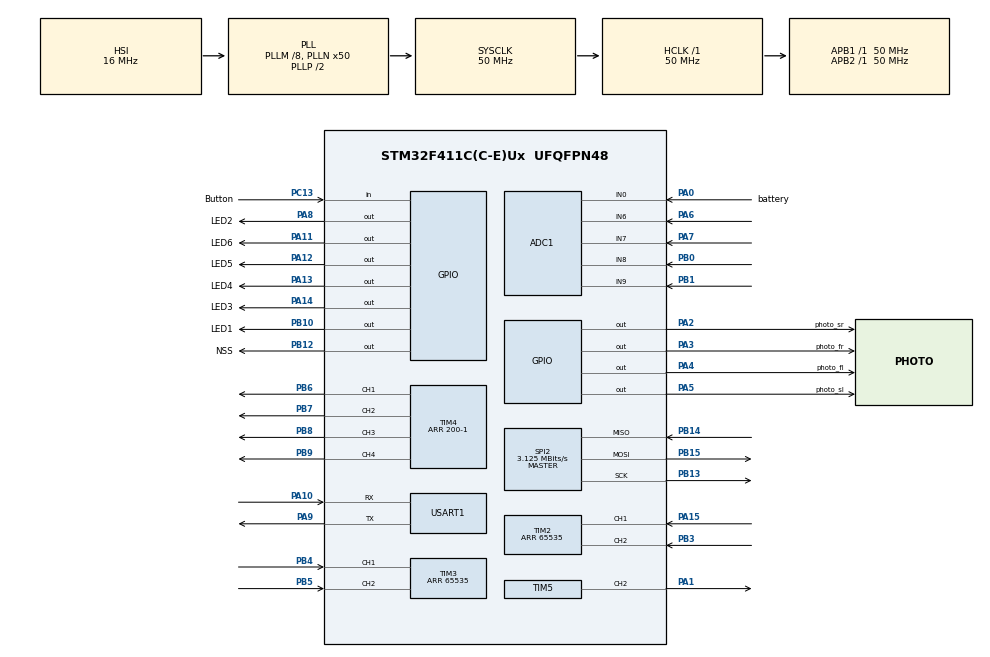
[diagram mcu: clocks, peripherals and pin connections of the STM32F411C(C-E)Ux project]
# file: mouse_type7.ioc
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ADC1.Channel-0\#ChannelRegularConversion=ADC_CHANNEL_7
ADC1.Channel-10\#ChannelRegularConversion=ADC_CHANNEL_0
ADC1.Channel-2\#ChannelRegularConversion=ADC_CHANNEL_7
ADC1.Channel-3\#ChannelRegularConversion=ADC_CHANNEL_8
ADC1.Channel-4\#ChannelRegularConversion=ADC_CHANNEL_8
ADC1.Channel-5\#ChannelRegularConversion=ADC_CHANNEL_6
ADC1.Channel-6\#ChannelRegularConversion=ADC_CHANNEL_6
ADC1.Channel-7\#ChannelRegularConversion=ADC_CHANNEL_9
ADC1.Channel-8\#ChannelRegularConversion=ADC_CHANNEL_9
ADC1.Channel-9\#ChannelRegularConversion=ADC_CHANNEL_0
ADC1.DMAContinuousRequests=ENABLE
ADC1.DiscontinuousConvMode=ENABLE
ADC1.EOCSelection=ADC_EOC_SEQ_CONV
ADC1.ExternalTrigConv=ADC_EXTERNALTRIGCONV_T1_CC3
ADC1.ExternalTrigConvEdge=ADC_EXTERNALTRIGCONVEDGE_FALLING
ADC1.NbrOfConversion=10
ADC1.NbrOfConversionFlag=1
ADC1.Rank-0\#ChannelRegularConversion=1
ADC1.Rank-10\#ChannelRegularConversion=10
ADC1.Rank-2\#ChannelRegularConversion=2
ADC1.Rank-3\#ChannelRegularConversion=3
ADC1.Rank-4\#ChannelRegularConversion=4
ADC1.Rank-5\#ChannelRegularConversion=5
ADC1.Rank-6\#ChannelRegularConversion=6
ADC1.Rank-7\#ChannelRegularConversion=7
ADC1.Rank-8\#ChannelRegularConversion=8
ADC1.Rank-9\#ChannelRegularConversion=9
ADC1.SamplingTime-0\#ChannelRegularConversion=ADC_SAMPLETIME_28CYCLES
ADC1.SamplingTime-10\#ChannelRegularConversion=ADC_SAMPLETIME_28CYCLES
ADC1.SamplingTime-2\#ChannelRegularConversion=ADC_SAMPLETIME_28CYCLES
ADC1.SamplingTime-3\#ChannelRegularConversion=ADC_SAMPLETIME_28CYCLES
ADC1.SamplingTime-4\#ChannelRegularConversion=ADC_SAMPLETIME_28CYCLES
ADC1.SamplingTime-5\#ChannelRegularConversion=ADC_SAMPLETIME_28CYCLES
ADC1.SamplingTime-6\#ChannelRegularConversion=ADC_SAMPLETIME_28CYCLES
ADC1.SamplingTime-7\#ChannelRegularConversion=ADC_SAMPLETIME_28CYCLES
ADC1.SamplingTime-8\#ChannelRegularConversion=ADC_SAMPLETIME_28CYCLES
ADC1.SamplingTime-9\#ChannelRegularConversion=ADC_SAMPLETIME_28CYCLES
ADC1.master=1
Dma.ADC1.0.Direction=DMA_PERIPH_TO_MEMORY
Dma.ADC1.0.FIFOMode=DMA_FIFOMODE_DISABLE
Dma.ADC1.0.Instance=DMA2_Stream0
Dma.ADC1.0.MemDataAlignment=DMA_MDATAALIGN_HALFWORD
Dma.ADC1.0.MemInc=DMA_MINC_ENABLE
Dma.ADC1.0.Mode=DMA_CIRCULAR
Dma.ADC1.0.PeriphDataAlignment=DMA_PDATAALIGN_HALFWORD
Dma.ADC1.0.PeriphInc=DMA_PINC_DISABLE
Dma.ADC1.0.Priority=DMA_PRIORITY_LOW
Dma.Request0=ADC1
Dma.Request1=TIM1_CH2
Dma.Request2=TIM1_CH4/TRIG/COM
Dma.Request3=SPI2_RX
Dma.Request4=SPI2_TX
Dma.Request5=USART1_RX
Dma.Request6=USART1_TX
Dma.SPI2_RX.3.Direction=DMA_PERIPH_TO_MEMORY
Dma.SPI2_RX.3.FIFOMode=DMA_FIFOMODE_DISABLE
Dma.SPI2_RX.3.Instance=DMA1_Stream3
Dma.SPI2_RX.3.MemDataAlignment=DMA_MDATAALIGN_BYTE
Dma.SPI2_RX.3.MemInc=DMA_MINC_ENABLE
Dma.SPI2_RX.3.Mode=DMA_NORMAL
Dma.SPI2_RX.3.PeriphDataAlignment=DMA_PDATAALIGN_BYTE
Dma.SPI2_RX.3.PeriphInc=DMA_PINC_DISABLE
Dma.SPI2_RX.3.Priority=DMA_PRIORITY_HIGH
Dma.SPI2_TX.4.Direction=DMA_MEMORY_TO_PERIPH
Dma.SPI2_TX.4.FIFOMode=DMA_FIFOMODE_DISABLE
Dma.SPI2_TX.4.Instance=DMA1_Stream4
Dma.SPI2_TX.4.MemDataAlignment=DMA_MDATAALIGN_BYTE
Dma.SPI2_TX.4.MemInc=DMA_MINC_ENABLE
Dma.SPI2_TX.4.Mode=DMA_NORMAL
Dma.SPI2_TX.4.PeriphDataAlignment=DMA_PDATAALIGN_BYTE
Dma.SPI2_TX.4.PeriphInc=DMA_PINC_DISABLE
Dma.SPI2_TX.4.Priority=DMA_PRIORITY_HIGH
Dma.TIM1_CH2.1.Direction=DMA_MEMORY_TO_PERIPH
Dma.TIM1_CH2.1.FIFOMode=DMA_FIFOMODE_DISABLE
Dma.TIM1_CH2.1.Instance=DMA2_Stream2
Dma.TIM1_CH2.1.MemDataAlignment=DMA_MDATAALIGN_WORD
Dma.TIM1_CH2.1.MemInc=DMA_MINC_ENABLE
Dma.TIM1_CH2.1.Mode=DMA_CIRCULAR
Dma.TIM1_CH2.1.PeriphDataAlignment=DMA_PDATAALIGN_WORD
Dma.TIM1_CH2.1.PeriphInc=DMA_PINC_DISABLE
Dma.TIM1_CH2.1.Priority=DMA_PRIORITY_HIGH
Dma.TIM1_CH4/TRIG/COM.2.Direction=DMA_MEMORY_TO_PERIPH
Dma.TIM1_CH4/TRIG/COM.2.FIFOMode=DMA_FIFOMODE_DISABLE
Dma.TIM1_CH4/TRIG/COM.2.Instance=DMA2_Stream4
Dma.TIM1_CH4/TRIG/COM.2.MemDataAlignment=DMA_MDATAALIGN_WORD
Dma.TIM1_CH4/TRIG/COM.2.MemInc=DMA_MINC_ENABLE
Dma.TIM1_CH4/TRIG/COM.2.Mode=DMA_CIRCULAR
Dma.TIM1_CH4/TRIG/COM.2.PeriphDataAlignment=DMA_PDATAALIGN_WORD
Dma.TIM1_CH4/TRIG/COM.2.PeriphInc=DMA_PINC_DISABLE
Dma.TIM1_CH4/TRIG/COM.2.Priority=DMA_PRIORITY_HIGH
Dma.USART1_RX.5.Direction=DMA_PERIPH_TO_MEMORY
Dma.USART1_RX.5.FIFOMode=DMA_FIFOMODE_DISABLE
Dma.USART1_RX.5.Instance=DMA2_Stream5
Dma.USART1_RX.5.MemDataAlignment=DMA_MDATAALIGN_BYTE
Dma.USART1_RX.5.MemInc=DMA_MINC_ENABLE
Dma.USART1_RX.5.Mode=DMA_NORMAL
Dma.USART1_RX.5.PeriphDataAlignment=DMA_PDATAALIGN_BYTE
Dma.USART1_RX.5.PeriphInc=DMA_PINC_DISABLE
Dma.USART1_RX.5.Priority=DMA_PRIORITY_LOW
Dma.USART1_TX.6.Direction=DMA_MEMORY_TO_PERIPH
Dma.USART1_TX.6.FIFOMode=DMA_FIFOMODE_DISABLE
Dma.USART1_TX.6.Instance=DMA2_Stream7
Dma.USART1_TX.6.MemDataAlignment=DMA_MDATAALIGN_BYTE
Dma.USART1_TX.6.MemInc=DMA_MINC_ENABLE
Dma.USART1_TX.6.Mode=DMA_NORMAL
Dma.USART1_TX.6.PeriphDataAlignment=DMA_PDATAALIGN_BYTE
Dma.USART1_TX.6.PeriphInc=DMA_PINC_DISABLE
Dma.USART1_TX.6.Priority=DMA_PRIORITY_LOW
Mcu.Family=STM32F4
Mcu.Name=STM32F411C(C-E)Ux
Mcu.Package=UFQFPN48
NVIC.DMA1_Stream3_IRQn=true\:0\:0\:false\:false\:true\:false\:true
NVIC.DMA1_Stream4_IRQn=true\:0\:0\:false\:false\:true\:false\:true
NVIC.DMA2_Stream0_IRQn=true\:0\:0\:false\:false\:true\:false\:true
NVIC.DMA2_Stream2_IRQn=true\:0\:0\:false\:false\:true\:false\:true
NVIC.DMA2_Stream4_IRQn=true\:0\:0\:false\:false\:true\:false\:true
NVIC.DMA2_Stream5_IRQn=true\:0\:0\:false\:false\:true\:false\:true
NVIC.DMA2_Stream7_IRQn=true\:0\:0\:false\:false\:true\:false\:true
NVIC.PriorityGroup=NVIC_PRIORITYGROUP_4
NVIC.TIM1_BRK_TIM9_IRQn=true\:0\:0\:false\:false\:true\:true\:true
NVIC.TIM1_TRG_COM_TIM11_IRQn=true\:0\:0\:false\:false\:true\:true\:true
NVIC.TIM5_IRQn=true\:0\:0\:false\:false\:true\:true\:true
NVIC.USART1_IRQn=true\:0\:0\:false\:false\:true\:true\:true
PA0-WKUP.GPIO_Label=battery
PA0-WKUP.Signal=ADCx_IN0
PA1.Signal=S_TIM5_CH2
PA10.Mode=Asynchronous
PA10.Signal=USART1_RX
PA11.GPIO_Label=LED6
PA11.Signal=GPIO_Output
PA12.GPIO_Label=LED5
PA12.Signal=GPIO_Output
PA13.GPIO_Label=LED4
PA13.Signal=GPIO_Output
PA14.GPIO_Label=LED3
PA14.Signal=GPIO_Output
PA15.Signal=S_TIM2_CH1_ETR
PA2.GPIO_Label=photo_sr
PA2.Signal=GPIO_Output
PA3.GPIO_Label=photo_fr
PA3.Signal=GPIO_Output
PA4.GPIO_Label=photo_fl
PA4.Signal=GPIO_Output
PA5.GPIO_Label=photo_sl
PA5.Signal=GPIO_Output
PA6.Signal=ADCx_IN6
PA7.Signal=ADCx_IN7
PA8.GPIO_Label=LED2
PA8.Signal=GPIO_Output
PA9.Mode=Asynchronous
PA9.Signal=USART1_TX
PB0.Signal=ADCx_IN8
PB1.Signal=ADCx_IN9
PB10.GPIO_Label=LED1
PB10.Signal=GPIO_Output
PB12.GPIO_Label=NSS
PB12.PinState=GPIO_PIN_RESET
PB12.Signal=GPIO_Output
PB13.Mode=Full_Duplex_Master
PB13.Signal=SPI2_SCK
PB14.Mode=Full_Duplex_Master
PB14.Signal=SPI2_MISO
PB15.Mode=Full_Duplex_Master
PB15.Signal=SPI2_MOSI
PB3.Signal=S_TIM2_CH2
PB4.Signal=S_TIM3_CH1
PB5.Signal=S_TIM3_CH2
PB6.Signal=S_TIM4_CH1
PB7.Signal=S_TIM4_CH2
PB8.Signal=S_TIM4_CH3
PB9.Signal=S_TIM4_CH4
PC13-ANTI_TAMP.GPIO_Label=Button
PC13-ANTI_TAMP.Signal=GPIO_Input
ProjectManager.HeapSize=0x200
ProjectManager.StackSize=0x400
ProjectManager.TargetToolchain=STM32CubeIDE
RCC.48MHZClocksFreq_Value=25000000
RCC.AHBFreq_Value=50000000
RCC.APB1Freq_Value=50000000
RCC.APB1TimFreq_Value=50000000
RCC.APB2Freq_Value=50000000
RCC.APB2TimFreq_Value=50000000
RCC.CortexFreq_Value=50000000
RCC.HCLKFreq_Value=50000000
RCC.HSE_VALUE=25000000
RCC.HSI_VALUE=16000000
RCC.LSE_VALUE=32768
RCC.PLLM=8
RCC.PLLN=50
RCC.SYSCLKFreq_VALUE=50000000
RCC.SYSCLKSource=RCC_SYSCLKSOURCE_PLLCLK
RCC.VCOOutputFreq_Value=100000000
SH.ADCx_IN0.0=ADC1_IN0,IN0
SH.ADCx_IN6.0=ADC1_IN6,IN6
SH.ADCx_IN7.0=ADC1_IN7,IN7
SH.ADCx_IN8.0=ADC1_IN8,IN8
SH.ADCx_IN9.0=ADC1_IN9,IN9
SH.S_TIM2_CH1_ETR.0=TIM2_CH1,Encoder_Interface
SH.S_TIM2_CH2.0=TIM2_CH2,Encoder_Interface
SH.S_TIM3_CH1.0=TIM3_CH1,Encoder_Interface
SH.S_TIM3_CH2.0=TIM3_CH2,Encoder_Interface
SH.S_TIM4_CH1.0=TIM4_CH1,PWM Generation1 CH1
SH.S_TIM4_CH2.0=TIM4_CH2,PWM Generation2 CH2
SH.S_TIM4_CH3.0=TIM4_CH3,PWM Generation3 CH3
SH.S_TIM4_CH4.0=TIM4_CH4,PWM Generation4 CH4
SH.S_TIM5_CH2.0=TIM5_CH2,PWM Generation2 CH2
SPI2.BaudRatePrescaler=SPI_BAUDRATEPRESCALER_16
SPI2.CLKPhase=SPI_PHASE_2EDGE
SPI2.CLKPolarity=SPI_POLARITY_HIGH
SPI2.CalculateBaudRate=3.125 MBits/s
SPI2.Direction=SPI_DIRECTION_2LINES
SPI2.Mode=SPI_MODE_MASTER
SPI2.VirtualType=VM_MASTER
TIM1.Channel-PWM\ Generation2\ No\ Output=TIM_CHANNEL_2
TIM1.Channel-PWM\ Generation3\ No\ Output=TIM_CHANNEL_3
TIM1.Channel-PWM\ Generation4\ No\ Output=TIM_CHANNEL_4
TIM1.Period=1000-1
TIM1.Prescaler=5-1
TIM1.Pulse-PWM\ Generation2\ No\ Output=2
TIM1.Pulse-PWM\ Generation3\ No\ Output=202
TIM1.Pulse-PWM\ Generation4\ No\ Output=252-1
TIM10.Channel=TIM_CHANNEL_1
TIM2.EncoderMode=TIM_ENCODERMODE_TI12
TIM2.IC1Filter=0
TIM2.IC1Polarity=TIM_ICPOLARITY_FALLING
TIM2.IC2Filter=0
TIM2.IC2Polarity=TIM_ICPOLARITY_FALLING
TIM2.Period=65535
TIM3.EncoderMode=TIM_ENCODERMODE_TI12
TIM3.IC1Filter=0
TIM3.IC1Polarity=TIM_ICPOLARITY_FALLING
TIM3.IC2Filter=0
TIM3.IC2Polarity=TIM_ICPOLARITY_FALLING
TIM3.Period=65535
TIM4.Channel-PWM\ Generation1\ CH1=TIM_CHANNEL_1
TIM4.Channel-PWM\ Generation2\ CH2=TIM_CHANNEL_2
TIM4.Channel-PWM\ Generation3\ CH3=TIM_CHANNEL_3
TIM4.Channel-PWM\ Generation4\ CH4=TIM_CHANNEL_4
TIM4.OCMode_PWM-PWM\ Generation3\ CH3=TIM_OCMODE_PWM1
TIM4.OCMode_PWM-PWM\ Generation4\ CH4=TIM_OCMODE_PWM1
TIM4.Period=200-1
TIM4.Pulse-PWM\ Generation3\ CH3=0
TIM4.Pulse-PWM\ Generation4\ CH4=0
TIM4.TIM_MasterOutputTrigger=TIM_TRGO_RESET
TIM5.Channel-PWM\ Generation2\ CH2=TIM_CHANNEL_2
TIM5.Period=1000-1
TIM5.Prescaler=0
USART1.VirtualMode=VM_ASYNC
VP_TIM10_VS_ClockSourceINT.Mode=Enable_Timer
VP_TIM10_VS_no_output1.Mode=Output Compare1 No Output
VP_TIM1_VS_ClockSourceINT.Mode=Internal
VP_TIM1_VS_no_output2.Mode=PWM Generation2 No Output
VP_TIM1_VS_no_output3.Mode=PWM Generation3 No Output
VP_TIM1_VS_no_output4.Mode=PWM Generation4 No Output
VP_TIM4_VS_ClockSourceINT.Mode=Internal
VP_TIM5_VS_ClockSourceINT.Mode=Internal
board=custom

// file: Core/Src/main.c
/* USER CODE BEGIN Header */
/**
  ******************************************************************************
  * @file           : main.c
  * @brief          : Main program body
  ******************************************************************************
  * @attention
  *
  * <h2><center>&copy; Copyright (c) 2023 STMicroelectronics.
  * All rights reserved.</center></h2>
  *
  * This software component is licensed by ST under BSD 3-Clause license,
  * the "License"; You may not use this file except in compliance with the
  * License. You may obtain a copy of the License at:
  *                        opensource.org/licenses/BSD-3-Clause
  *
  ******************************************************************************
  */
/* USER CODE END Header */

#include "main.h"
#include "adc.h"
#include "dma.h"
#include "spi.h"
#include "tim.h"
#include "usart.h"
#include "gpio.h"

/* USER CODE BEGIN Includes */
#include "../CPP/Module/Inc/communicate.h"
#include "../CPP/Pheripheral/Include/index.h"
#include <stdio.h>
/* USER CODE END Includes */

void SystemClock_Config(void);

int main(void)
{
  /* USER CODE BEGIN 1 */
	//setbuf(stdout, NULL);
  /* USER CODE END 1 */

  /* MCU Configuration--------------------------------------------------------*/

  /* Reset of all peripherals, Initializes the Flash interface and the Systick. */
  HAL_Init();

  /* Configure the system clock */
  SystemClock_Config();

  /* Initialize all configured peripherals */
  MX_GPIO_Init();
  MX_DMA_Init();
  MX_ADC1_Init();
  MX_TIM1_Init();
  MX_TIM2_Init();
  MX_TIM3_Init();
  MX_TIM4_Init();
  MX_SPI2_Init();
  MX_TIM10_Init();
  MX_USART1_UART_Init();
  MX_TIM5_Init();
  /* USER CODE BEGIN 2 */
  CPP_Main();
  /* USER CODE END 2 */

  /* Infinite loop */
  while (1)
  {

    /* USER CODE BEGIN 3 */
	 //CPP_Main();

	  }

  /* USER CODE END 3 */
}

void SystemClock_Config(void)
{
  RCC_OscInitTypeDef RCC_OscInitStruct = {0};
  RCC_ClkInitTypeDef RCC_ClkInitStruct = {0};

  /** Configure the main internal regulator output voltage
  */
  __HAL_RCC_PWR_CLK_ENABLE();
  __HAL_PWR_VOLTAGESCALING_CONFIG(PWR_REGULATOR_VOLTAGE_SCALE1);
  /** Initializes the CPU, AHB and APB busses clocks
  */
  RCC_OscInitStruct.OscillatorType = RCC_OSCILLATORTYPE_HSI;
  RCC_OscInitStruct.HSIState = RCC_HSI_ON;
  RCC_OscInitStruct.HSICalibrationValue = RCC_HSICALIBRATION_DEFAULT;
  RCC_OscInitStruct.PLL.PLLState = RCC_PLL_ON;
  RCC_OscInitStruct.PLL.PLLSource = RCC_PLLSOURCE_HSI;
  RCC_OscInitStruct.PLL.PLLM = 8;
  RCC_OscInitStruct.PLL.PLLN = 50;
  RCC_OscInitStruct.PLL.PLLP = RCC_PLLP_DIV2;
  RCC_OscInitStruct.PLL.PLLQ = 4;
  if (HAL_RCC_OscConfig(&RCC_OscInitStruct) != HAL_OK)
  {
    Error_Handler();
  }
  /** Initializes the CPU, AHB and APB busses clocks
  */
  RCC_ClkInitStruct.ClockType = RCC_CLOCKTYPE_HCLK|RCC_CLOCKTYPE_SYSCLK
                              |RCC_CLOCKTYPE_PCLK1|RCC_CLOCKTYPE_PCLK2;
  RCC_ClkInitStruct.SYSCLKSource = RCC_SYSCLKSOURCE_PLLCLK;
  RCC_ClkInitStruct.AHBCLKDivider = RCC_SYSCLK_DIV1;
  RCC_ClkInitStruct.APB1CLKDivider = RCC_HCLK_DIV1;
  RCC_ClkInitStruct.APB2CLKDivider = RCC_HCLK_DIV1;

  if (HAL_RCC_ClockConfig(&RCC_ClkInitStruct, FLASH_LATENCY_1) != HAL_OK)
  {
    Error_Handler();
  }
}

/* USER CODE BEGIN 4 */
/*
int _write(int file, char *ptr, int len)
{
  HAL_UART_Transmit(&huart1,(uint8_t *)ptr,len,10);
  return len;
}
*/
/* USER CODE END 4 */

void Error_Handler(void)
{
}

/************************ (C) COPYRIGHT STMicroelectronics *****END OF FILE****/
